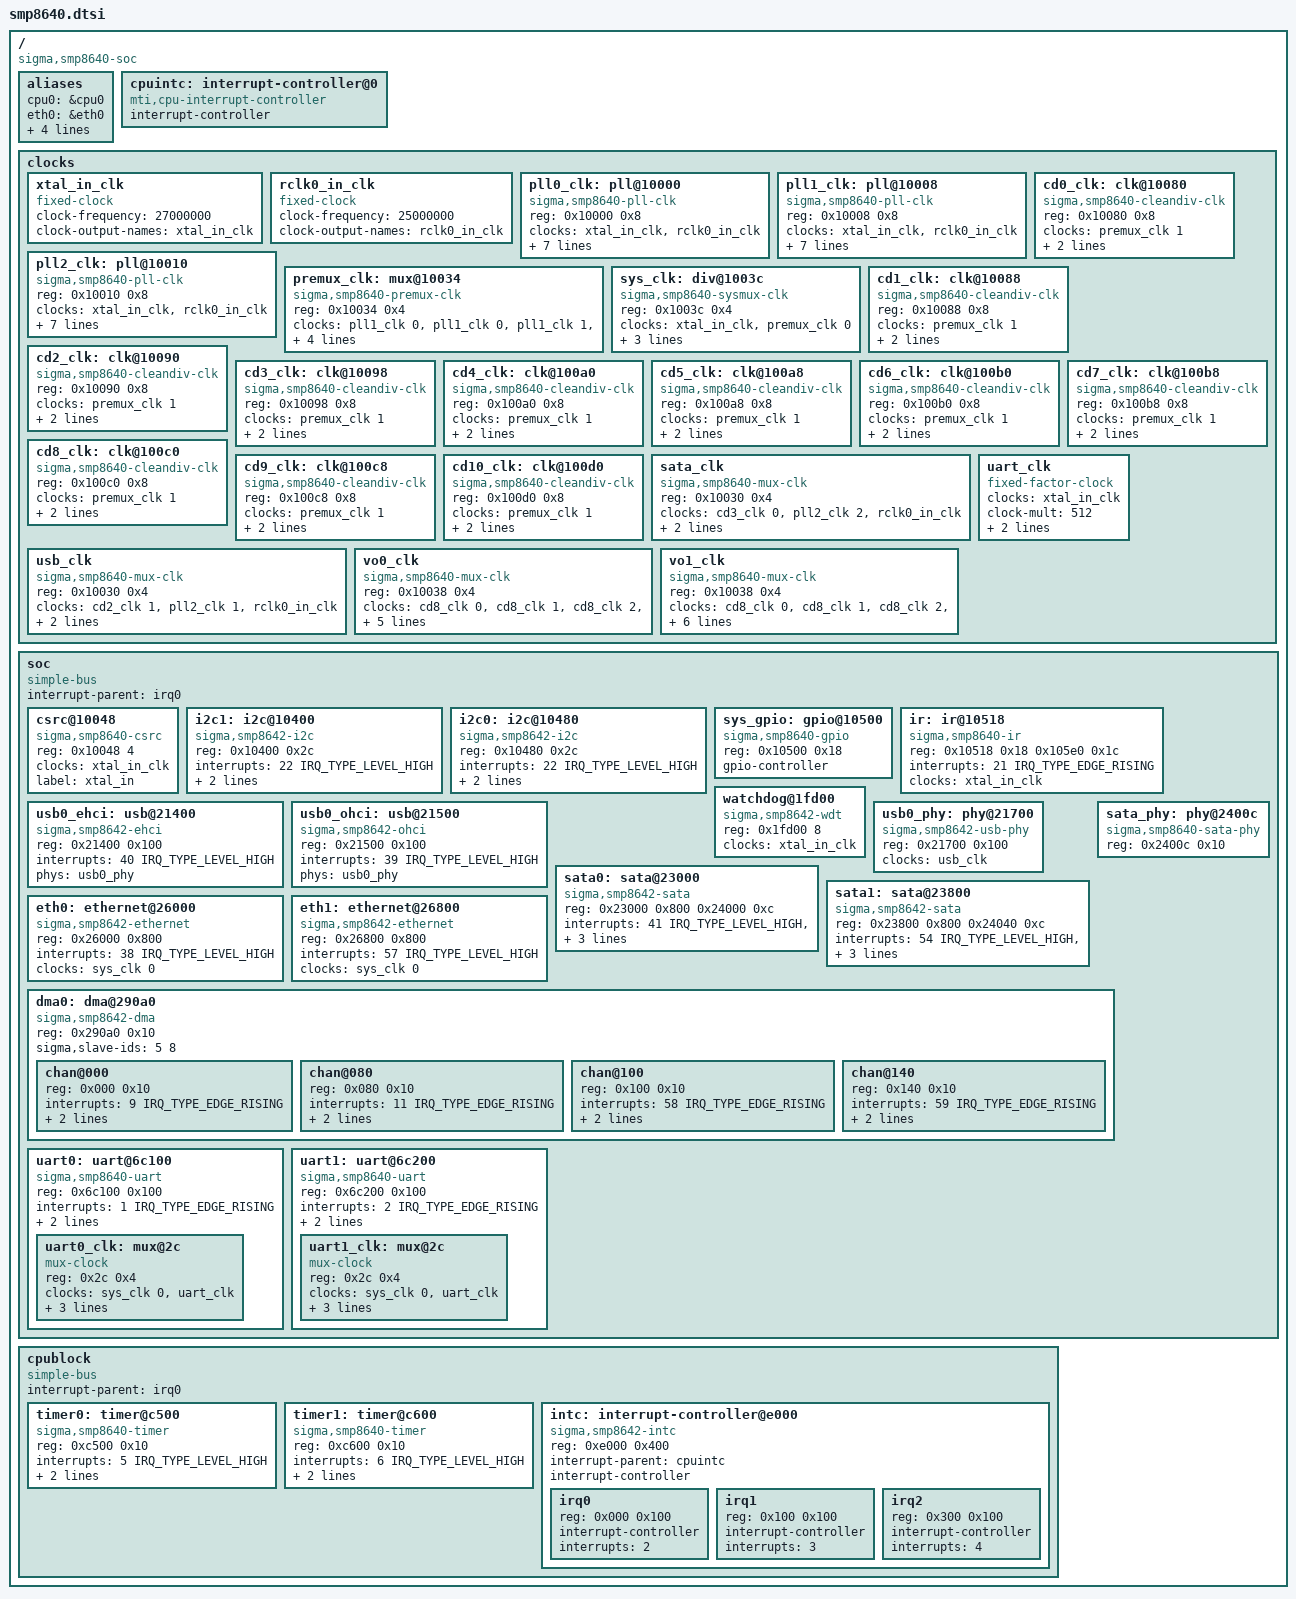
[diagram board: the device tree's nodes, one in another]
#include <dt-bindings/interrupt-controller/irq.h>

/ {
	compatible = "sigma,smp8640-soc";

	#address-cells = <1>;
	#size-cells = <1>;

	aliases {
		cpu0 = &cpu0;
		eth0 = &eth0;
		eth1 = &eth1;
		i2c0 = &i2c0;
		i2c1 = &i2c1;
		sata_phy = &sata_phy;
	};

	cpuintc: interrupt-controller@0 {
		compatible = "mti,cpu-interrupt-controller";
		#address-cells = <0>;
		interrupt-controller;
		#interrupt-cells = <1>;
	};

	clocks {
		ranges;
		#address-cells = <1>;
		#size-cells = <1>;

		xtal_in_clk: xtal_in_clk {
			compatible = "fixed-clock";
			#clock-cells = <0>;
			clock-frequency = <27000000>;
			clock-output-names = "xtal_in_clk";
		};

		rclk0_in_clk: rclk0_in_clk {
			compatible = "fixed-clock";
			#clock-cells = <0>;
			clock-frequency = <25000000>;
			clock-output-names = "rclk0_in_clk";
		};

		pll0_clk: pll@10000 {
			compatible = "sigma,smp8640-pll-clk";
			reg = <0x10000 0x8>;
			#clock-cells = <1>;
			clocks = <&xtal_in_clk>, <&rclk0_in_clk>;
			clock-output-names = "pll0_clk",
					     "pll0_d1_clk",
					     "pll0_d2_clk";
			sigma,mux-table = <1 4>;
			sigma,pll-n-bits = <10>;
			sigma,pll-m-bits = <5>;
			sigma,pll-k-bits = <2 14>;
			sigma,pll-mn-bias = <2>;
		};

		pll1_clk: pll@10008 {
			compatible = "sigma,smp8640-pll-clk";
			reg = <0x10008 0x8>;
			#clock-cells = <1>;
			clocks = <&xtal_in_clk>, <&rclk0_in_clk>;
			clock-output-names = "pll1_clk",
					     "pll1_d1_clk",
					     "pll1_d2_clk";
			sigma,mux-table = <1 4>;
			sigma,pll-n-bits = <7>;
			sigma,pll-m-bits = <1>;
			sigma,pll-k-bits = <3 13>;
			sigma,pll-mn-bias = <1>;
		};

		pll2_clk: pll@10010 {
			compatible = "sigma,smp8640-pll-clk";
			reg = <0x10010 0x8>;
			#clock-cells = <1>;
			clocks = <&xtal_in_clk>, <&rclk0_in_clk>;
			clock-output-names = "pll2_clk",
					     "pll2_d1_clk",
					     "pll2_d2_clk";
			sigma,mux-table = <1 4>;
			sigma,pll-n-bits = <7>;
			sigma,pll-m-bits = <1>;
			sigma,pll-k-bits = <3 13>;
			sigma,pll-mn-bias = <1>;
		};

		premux_clk: mux@10034 {
			compatible = "sigma,smp8640-premux-clk";
			reg = <0x10034 0x4>;
			#clock-cells = <1>;
			clocks = <&pll1_clk 0>,
				 <&pll1_clk 0>, <&pll1_clk 1>,
				 <&pll2_clk 0>, <&pll2_clk 1>;
			clock-output-names = "pll_sys_clk", "cd_clk";
			sigma,sys-table = <1>;
			sigma,cd-table = <2 3 4 5>;
		};

		sys_clk: div@1003c {
			compatible = "sigma,smp8640-sysmux-clk";
			reg = <0x1003c 0x4>;
			#clock-cells = <1>;
			clocks = <&xtal_in_clk>, <&premux_clk 0>;
			clock-output-names = "sys_clk", "cpu_clk", "dsp_clk";
			sigma,divisors = <2 4 3 3 3 3 3 3 4 4 4 4
					  2 2 2 3 3 2 3 2 4 2 4 2
					  2 4 3 3 3 3 3 3 4 4 4 4>;
		};

		cd0_clk: clk@10080 {
			compatible = "sigma,smp8640-cleandiv-clk";
			reg = <0x10080 0x8>;
			#clock-cells = <1>;
			clocks = <&premux_clk 1>;
			clock-output-names = "cd0_clk",
					     "cd0_2_clk",
					     "cd0_4_clk";
		};

		cd1_clk: clk@10088 {
			compatible = "sigma,smp8640-cleandiv-clk";
			reg = <0x10088 0x8>;
			#clock-cells = <1>;
			clocks = <&premux_clk 1>;
			clock-output-names = "cd1_clk",
					     "cd1_2_clk",
					     "cd1_4_clk";
		};

		cd2_clk: clk@10090 {
			compatible = "sigma,smp8640-cleandiv-clk";
			reg = <0x10090 0x8>;
			#clock-cells = <1>;
			clocks = <&premux_clk 1>;
			clock-output-names = "cd2_clk",
					     "cd2_2_clk",
					     "cd2_4_clk";
		};

		cd3_clk: clk@10098 {
			compatible = "sigma,smp8640-cleandiv-clk";
			reg = <0x10098 0x8>;
			#clock-cells = <1>;
			clocks = <&premux_clk 1>;
			clock-output-names = "cd3_clk",
					     "cd3_2_clk",
					     "cd3_4_clk";
		};

		cd4_clk: clk@100a0 {
			compatible = "sigma,smp8640-cleandiv-clk";
			reg = <0x100a0 0x8>;
			#clock-cells = <1>;
			clocks = <&premux_clk 1>;
			clock-output-names = "cd4_clk",
					     "cd4_2_clk",
					     "cd4_4_clk";
		};

		cd5_clk: clk@100a8 {
			compatible = "sigma,smp8640-cleandiv-clk";
			reg = <0x100a8 0x8>;
			#clock-cells = <1>;
			clocks = <&premux_clk 1>;
			clock-output-names = "cd5_clk",
					     "cd5_2_clk",
					     "cd5_4_clk";
		};

		cd6_clk: clk@100b0 {
			compatible = "sigma,smp8640-cleandiv-clk";
			reg = <0x100b0 0x8>;
			#clock-cells = <1>;
			clocks = <&premux_clk 1>;
			clock-output-names = "cd6_clk",
					     "cd6_2_clk",
					     "cd6_4_clk";
		};

		cd7_clk: clk@100b8 {
			compatible = "sigma,smp8640-cleandiv-clk";
			reg = <0x100b8 0x8>;
			#clock-cells = <1>;
			clocks = <&premux_clk 1>;
			clock-output-names = "cd7_clk",
					     "cd7_2_clk",
					     "cd7_4_clk";
		};

		cd8_clk: clk@100c0 {
			compatible = "sigma,smp8640-cleandiv-clk";
			reg = <0x100c0 0x8>;
			#clock-cells = <1>;
			clocks = <&premux_clk 1>;
			clock-output-names = "cd8_clk",
					     "cd8_2_clk",
					     "cd8_4_clk";
		};

		cd9_clk: clk@100c8 {
			compatible = "sigma,smp8640-cleandiv-clk";
			reg = <0x100c8 0x8>;
			#clock-cells = <1>;
			clocks = <&premux_clk 1>;
			clock-output-names = "cd9_clk",
					     "cd9_2_clk",
					     "cd9_4_clk";
		};

		cd10_clk: clk@100d0 {
			compatible = "sigma,smp8640-cleandiv-clk";
			reg = <0x100d0 0x8>;
			#clock-cells = <1>;
			clocks = <&premux_clk 1>;
			clock-output-names = "cd10_clk",
					     "cd10_2_clk",
					     "cd10_4_clk";
		};

		sata_clk: sata_clk {
			compatible = "sigma,smp8640-mux-clk";
			reg = <0x10030 0x4>;
			#clock-cells = <0>;
			clocks = <&cd3_clk 0>, <&pll2_clk 2>, <&rclk0_in_clk>;
			clock-output-names = "sata_clk";
			sigma,bits = <4 4>;
		};

		usb_clk: usb_clk {
			compatible = "sigma,smp8640-mux-clk";
			reg = <0x10030 0x4>;
			#clock-cells = <0>;
			clocks = <&cd2_clk 1>, <&pll2_clk 1>, <&rclk0_in_clk>;
			clock-output-names = "usb_clk";
			sigma,bits = <8 4>;
		};

		vo0_clk: vo0_clk {
			compatible = "sigma,smp8640-mux-clk";
			reg = <0x10038 0x4>;
			#clock-cells = <0>;
			clocks = <&cd8_clk 0>, <&cd8_clk 1>, <&cd8_clk 2>,
				 <&cd8_clk 1>, <&cd8_clk 2>,
				 <&pll1_clk 1>, <&pll1_clk 2>, <&pll2_clk 1>;
			clock-output-names = "vo0_clk";
			sigma,bits = <0 4>;
			sigma,mux-table = <1 2 3 4 5 10 11 12>;
		};

		vo1_clk: vo1_clk {
			compatible = "sigma,smp8640-mux-clk";
			reg = <0x10038 0x4>;
			#clock-cells = <0>;
			clocks = <&cd8_clk 0>, <&cd8_clk 1>, <&cd8_clk 2>,
				 <&cd9_clk 0>, <&cd9_clk 1>, <&cd9_clk 2>,
				 <&cd10_clk 0>, <&cd10_clk 1>, <&cd10_clk 2>,
				 <&pll1_clk 1>, <&pll1_clk 2>, <&pll2_clk 1>,
				 <&pll1_clk 0>, <&rclk0_in_clk>;
			clock-output-names = "vo1_clk";
			sigma,bits = <4 4>;
		};

		uart_clk: uart_clk {
			compatible = "fixed-factor-clock";
			#clock-cells = <0>;
			clocks = <&xtal_in_clk>;
			clock-mult = <512>;
			clock-div = <1875>;
			clock-output-names = "uart_clk";
		};
	};

	soc {
		compatible = "simple-bus";
		interrupt-parent = <&irq0>;
		#address-cells = <1>;
		#size-cells = <1>;
		ranges;

		csrc@10048 {
			compatible = "sigma,smp8640-csrc";
			reg = <0x10048 4>;
			clocks = <&xtal_in_clk>;
			label = "xtal_in";
		};

		i2c1: i2c@10400 {
			compatible = "sigma,smp8642-i2c";
			reg = <0x10400 0x2c>;
			interrupts = <22 IRQ_TYPE_LEVEL_HIGH>;
			clocks = <&sys_clk 0>;
			clock-frequency = <100000>;
			#address-cells = <1>;
			#size-cells = <0>;
		};

		i2c0: i2c@10480 {
			compatible = "sigma,smp8642-i2c";
			reg = <0x10480 0x2c>;
			interrupts = <22 IRQ_TYPE_LEVEL_HIGH>;
			clocks = <&sys_clk 0>;
			clock-frequency = <100000>;
			#address-cells = <1>;
			#size-cells = <0>;
		};

		sys_gpio: gpio@10500 {
			compatible = "sigma,smp8640-gpio";
			reg = <0x10500 0x18>;
			gpio-controller;
			#gpio-cells = <2>;
		};

		ir: ir@10518 {
			compatible = "sigma,smp8640-ir";
			reg = <0x10518 0x18
			       0x105e0 0x1c>;
			interrupts = <21 IRQ_TYPE_EDGE_RISING>;
			clocks = <&xtal_in_clk>;
		};

		watchdog@1fd00 {
			compatible = "sigma,smp8642-wdt";
			reg = <0x1fd00 8>;
			clocks = <&xtal_in_clk>;
		};

		usb0_ehci: usb@21400 {
			compatible = "sigma,smp8642-ehci", "generic-ehci";
			reg = <0x21400 0x100>;
			interrupts = <40 IRQ_TYPE_LEVEL_HIGH>;
			phys = <&usb0_phy>;
			phy-names = "usb";
		};

		usb0_ohci: usb@21500 {
			compatible = "sigma,smp8642-ohci", "generic-ohci";
			reg = <0x21500 0x100>;
			interrupts = <39 IRQ_TYPE_LEVEL_HIGH>;
			phys = <&usb0_phy>;
			phy-names = "usb";
		};

		usb0_phy: phy@21700 {
			compatible = "sigma,smp8642-usb-phy";
			reg = <0x21700 0x100>;
			#phy-cells = <0>;
			clocks = <&usb_clk>;
		};

		sata0: sata@23000 {
			compatible = "sigma,smp8642-sata";
			reg = <0x23000 0x800 0x24000 0xc>;
			interrupts = <41 IRQ_TYPE_LEVEL_HIGH>,
				     <42 IRQ_TYPE_LEVEL_HIGH>;
			dmas = <&dma0 5>;
			dma-names = "sata-dma";
			phys = <&sata_phy>;
			phy-names = "sata-phy";
		};

		sata1: sata@23800 {
			compatible = "sigma,smp8642-sata";
			reg = <0x23800 0x800 0x24040 0xc>;
			interrupts = <54 IRQ_TYPE_LEVEL_HIGH>,
				     <55 IRQ_TYPE_LEVEL_HIGH>;
			dmas = <&dma0 8>;
			dma-names = "sata-dma";
			phys = <&sata_phy>;
			phy-names = "sata-phy";
		};

		sata_phy: phy@2400c {
			compatible = "sigma,smp8640-sata-phy";
			reg = <0x2400c 0x10>;
			#phy-cells = <0>;
		};

		eth0: ethernet@26000 {
			compatible = "sigma,smp8642-ethernet";
			reg = <0x26000 0x800>;
			interrupts = <38 IRQ_TYPE_LEVEL_HIGH>;
			clocks = <&sys_clk 0>;
			#address-cells = <1>;
			#size-cells = <0>;
		};

		eth1: ethernet@26800 {
			compatible = "sigma,smp8642-ethernet";
			reg = <0x26800 0x800>;
			interrupts = <57 IRQ_TYPE_LEVEL_HIGH>;
			clocks = <&sys_clk 0>;
			#address-cells = <1>;
			#size-cells = <0>;
		};

		dma0: dma@290a0 {
			compatible = "sigma,smp8642-dma";
			reg = <0x290a0 0x10>;
			ranges = <0x0 0x2b000 0x200>;
			#dma-cells = <1>;
			sigma,slave-ids = <5 8>;
			#address-cells = <1>;
			#size-cells = <1>;

			chan@000 {
				reg = <0x000 0x10>;
				interrupts = <9 IRQ_TYPE_EDGE_RISING>;
				sigma,sbox-id = <1>;
				sigma,dev-to-mem;
			};

			chan@080 {
				reg = <0x080 0x10>;
				interrupts = <11 IRQ_TYPE_EDGE_RISING>;
				sigma,sbox-id = <1>;
				sigma,mem-to-dev;
			};

			chan@100 {
				reg = <0x100 0x10>;
				interrupts = <58 IRQ_TYPE_EDGE_RISING>;
				sigma,sbox-id = <9>;
				sigma,dev-to-mem;
			};

			chan@140 {
				reg = <0x140 0x10>;
				interrupts = <59 IRQ_TYPE_EDGE_RISING>;
				sigma,sbox-id = <9>;
				sigma,mem-to-dev;
			};
		};

		uart0: uart@6c100 {
			compatible = "sigma,smp8640-uart", "ralink,rt2880-uart";
			reg = <0x6c100 0x100>;
			ranges = <0x0 0x6c100 0x100>;
			interrupts = <1 IRQ_TYPE_EDGE_RISING>;
			clocks = <&uart0_clk>;
			reg-shift = <2>;

			#address-cells = <1>;
			#size-cells = <1>;

			uart0_clk: mux@2c {
				compatible = "mux-clock";
				reg = <0x2c 0x4>;
				#clock-cells = <0>;
				clocks = <&sys_clk 0>, <&uart_clk>;
				clock-output-names = "uart0_clk";
				clock-mux-shift = <0>;
				clock-mux-width = <1>;
			};
		};

		uart1: uart@6c200 {
			compatible = "sigma,smp8640-uart", "ralink,rt2880-uart";
			reg = <0x6c200 0x100>;
			ranges = <0x0 0x6c200 0x100>;
			interrupts = <2 IRQ_TYPE_EDGE_RISING>;
			clocks = <&uart1_clk>;
			reg-shift = <2>;

			#address-cells = <1>;
			#size-cells = <1>;

			uart1_clk: mux@2c {
				compatible = "mux-clock";
				reg = <0x2c 0x4>;
				#clock-cells = <0>;
				clocks = <&sys_clk 0>, <&uart_clk>;
				clock-output-names = "uart1_clk";
				clock-mux-shift = <0>;
				clock-mux-width = <1>;
			};
		};
	};


	cpublock: cpublock {
		compatible = "simple-bus";
		interrupt-parent = <&irq0>;
		#address-cells = <1>;
		#size-cells = <1>;

		timer0: timer@c500 {
			compatible = "sigma,smp8640-timer";
			reg = <0xc500 0x10>;
			interrupts = <5 IRQ_TYPE_LEVEL_HIGH>;
			clocks = <&sys_clk 0>;
			label = "tangox_timer0";
		};

		timer1: timer@c600 {
			compatible = "sigma,smp8640-timer";
			reg = <0xc600 0x10>;
			interrupts = <6 IRQ_TYPE_LEVEL_HIGH>;
			clocks = <&xtal_in_clk>;
			label = "tangox_timer1";
		};

		intc: interrupt-controller@e000 {
			compatible = "sigma,smp8642-intc";
			reg = <0xe000 0x400>;
			ranges = <0x0 0xe000 0x400>;
			interrupt-parent = <&cpuintc>;
			interrupt-controller;
			#address-cells = <1>;
			#size-cells = <1>;

			irq0: irq0 {
				reg = <0x000 0x100>;
				interrupt-controller;
				#interrupt-cells = <2>;
				interrupts = <2>;
			};

			irq1: irq1 {
				reg = <0x100 0x100>;
				interrupt-controller;
				#interrupt-cells = <2>;
				interrupts = <3>;
			};

			irq2: irq2 {
				reg = <0x300 0x100>;
				interrupt-controller;
				#interrupt-cells = <2>;
				interrupts = <4>;
			};
		};
	};
};
